# MKW21Z4 register map
Vendor: Freescale Semiconductor, Inc.; Series: Kinetis_W; File version: 1.6
CPU: CM0PLUS r0p0, little endian, no MPU, no FPU, VTOR, 2 interrupt priority bits
Registers are 16-bit, read-write, no defined reset value unless marked. A register's access mark holds for its fields unless they carry their own. Offsets are from the block's base; [hi:lo] are bit positions; {n}, {i} and the like mark numbered series.

## XCVR_CTRL_REGS — XCVR_MISC
Base 0x4005C280
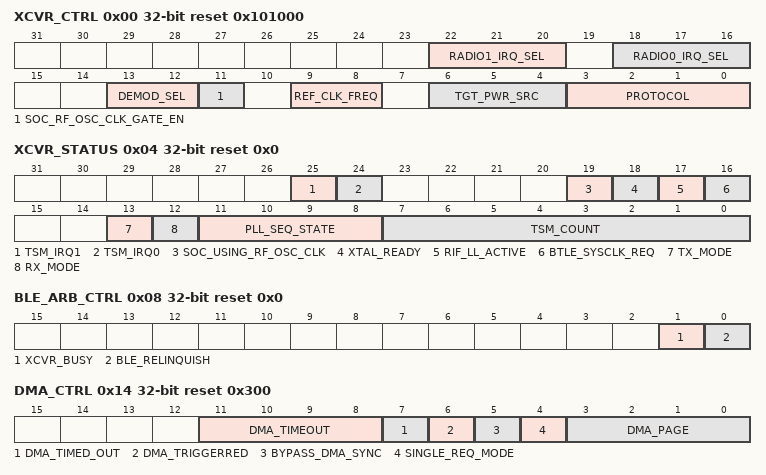
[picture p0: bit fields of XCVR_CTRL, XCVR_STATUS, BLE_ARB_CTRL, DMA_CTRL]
0x00 XCVR_CTRL 32-bit reset 0x101000 — TRANSCEIVER CONTROL
  [22:20] RADIO1_IRQ_SEL
    0=Assign Radio #1 Interrupt to BLE; 1=Assign Radio #1 Interrupt to 802.15.4; 2=Assign Radio #1 Interrupt to ANT; 3=Assign Radio #1 Interrupt to GENERIC_FSK; {v}=Radio #1 Interrupt unassigned (v=4..7)
  [18:16] RADIO0_IRQ_SEL
    0=Assign Radio #0 Interrupt to BLE; 1=Assign Radio #0 Interrupt to 802.15.4; 2=Assign Radio #0 Interrupt to ANT; 3=Assign Radio #0 Interrupt to GENERIC_FSK; {v}=Radio #0 Interrupt unassigned (v=4..7)
  [13:12] DEMOD_SEL — Demodulator Selector
    0=No demodulator selected; 1=Use Freescale Constant Envelope demodulator; 2=Use Legacy 802.15.4 demodulator
  [11] SOC_RF_OSC_CLK_GATE_EN
  [9:8] REF_CLK_FREQ — Radio Reference Clock Frequency
    0=32 MHz; 1=26 MHz
  [6:4] TGT_PWR_SRC — Target Power Source
  [3:0] PROTOCOL — Radio Protocol Selection
    0=BLE; 1=BLE in MBAN; 2=BLE overlap MBAN; 3=ANT; 4=Zigbee; 5=802.15.4j; 6=128 Channel FSK; 7=128 Channel GFSK; 8=Generic FSK; 9=MSK
0x04 XCVR_STATUS 32-bit reset 0x0 (reset mask 0xFFF0C000) — TRANSCEIVER STATUS
  [25] TSM_IRQ1 — TSM Interrupt #1
    0=TSM Interrupt #1 is not asserted; 1=TSM Interrupt #1 is asserted. Write '1' to this bit to clear it.
  [24] TSM_IRQ0 — TSM Interrupt #0
    0=TSM Interrupt #0 is not asserted; 1=TSM Interrupt #0 is asserted. Write '1' to this bit to clear it.
  [19] SOC_USING_RF_OSC_CLK ro — SOC Using RF Clock Indication
  [18] XTAL_READY ro — RF Osciallator Xtal Ready
    0=Indicates that the RF Oscillator is disabled or has not completed its warmup; 1=Indicates that the RF Oscillator has completed its warmup count and is ready for use
  [17] RIF_LL_ACTIVE ro — Link Layer Active Indication
  [16] BTLE_SYSCLK_REQ ro — BTLE System Clock Request
  [13] TX_MODE ro — Transmit Mode
  [12] RX_MODE ro — Receive Mode
  [11:8] PLL_SEQ_STATE ro — PLL Sequence State
    0=PLL OFF; 2=CTUNE; 3=CTUNE_SETTLE; 6=HPMCAL1; 8=HPMCAL1_SETTLE; 10=HPMCAL2; 12=HPMCAL2_SETTLE; 15=PLLREADY
  [7:0] TSM_COUNT ro
0x08 BLE_ARB_CTRL 32-bit reset 0x0 — BLE ARBITRATION CONTROL
  [1] XCVR_BUSY ro — Transceiver Busy Status Bit
    0=RF Channel in available (TSM is idle); 1=RF Channel in use (TSM is busy)
  [0] BLE_RELINQUISH — BLE Relinquish Control
0x10 OVERWRITE_VER 32-bit reset 0x0 — OVERWRITE VERSION
  [7:0] OVERWRITE_VER — Overwrite Version Number.
0x14 DMA_CTRL 32-bit reset 0x300 — TRANSCEIVER DMA CONTROL
  [11:8] DMA_TIMEOUT
  [7] DMA_TIMED_OUT — DMA Transfer Timed Out
    0=A DMA timeout has not occurred; 1=A DMA timeout has occurred in Single Request Mode since the last time this bit was cleared
  [6] DMA_TRIGGERRED ro
  [5] BYPASS_DMA_SYNC — Bypass External DMA Synchronization
    0=Don't Bypass External Synchronization. Use this setting if SINGLE_REQ_MODE=1.; 1=Bypass External Synchronization. This setting is mandatory if SINGLE_REQ_MODE=0.
  [4] SINGLE_REQ_MODE — DMA Single Request Mode
    0=Disable Single Request Mode. The transceiver will assert ipd_req_radio_rx whenever it has a new sample ready for transfer.; 1=Enable Single Request Mode. A single initial request by the transceiver will transfer the entire DMA block of data
  [3:0] DMA_PAGE — Transceiver DMA Page Selector
    0=DMA Idle; 1=RX_DIG I and Q; 2=RX_DIG I Only; 3=RX_DIG Q Only; 4=RAW ADC I and Q; 5=RAW ADC I Only; 6=RAW ADC Q only; 7=DC Estimator I and Q; 8=DC Estimator I Only; 9=DC Estimator Q only; 10=RX_DIG Phase Output; 11=Demodulator Hard Decision; 12=Demodulator Soft Decision; 13=Demodulator Data Output; 14=Demodulator CFO Phase Output
0x18 DMA_DATA 32-bit ro reset 0x0 — TRANSCEIVER DMA DATA
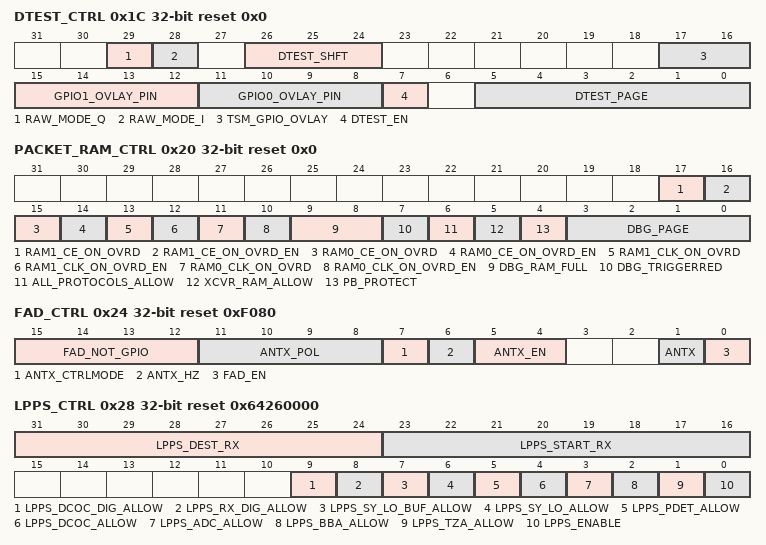
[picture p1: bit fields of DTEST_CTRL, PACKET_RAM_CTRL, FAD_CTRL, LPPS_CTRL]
0x1C DTEST_CTRL 32-bit reset 0x0 — DIGITAL TEST MUX CONTROL
  [29] RAW_MODE_Q — DTEST Raw Mode Enable for Q Channel
  [28] RAW_MODE_I — DTEST Raw Mode Enable for I Channel
  [26:24] DTEST_SHFT — DTEST Shift Control
  [17:16] TSM_GPIO_OVLAY — TSM GPIO Overlay Pin Control
    0=there is no overlay, and the DTEST Page Table dictates the node that appears on each DTEST pin; 1=the register GPIO0_OVLAY_PIN[3:0] selects the DTEST pin on which GPIO0_TRIG_EN will appear
  [15:12] GPIO1_OVLAY_PIN — GPIO 1 Overlay Pin
  [11:8] GPIO0_OVLAY_PIN — GPIO 0 Overlay Pin
  [7] DTEST_EN — DTEST Enable
    0=Disables DTEST. The DTEST pins assume their mission function.; 1=Enables DTEST. The contents of the selected page (DTEST_PAGE) will appear on the DTEST output pins.
  [5:0] DTEST_PAGE — DTEST Page Selector
0x20 PACKET_RAM_CTRL 32-bit reset 0x0 — PACKET RAM CONTROL
  [17] RAM1_CE_ON_OVRD — Override value for RAM1 CE (Chip Enable)
  [16] RAM1_CE_ON_OVRD_EN — Override control for RAM1 CE (Chip Enable)
    0=Normal operation; 1=Use the state of RAM1_CE_ON_OVRD to override the RAM1 CE
  [15] RAM0_CE_ON_OVRD — Override value for RAM0 CE (Chip Enable)
  [14] RAM0_CE_ON_OVRD_EN — Override control for RAM0 CE (Chip Enable)
    0=Normal operation; 1=Use the state of RAM0_CE_ON_OVRD to override the RAM0 CE
  [13] RAM1_CLK_ON_OVRD — Override value for RAM1 Clock Gate Enable
  [12] RAM1_CLK_ON_OVRD_EN — Override control for RAM1 Clock Gate Enable
    0=Normal operation; 1=Use the state of RAM1_CLK_ON_OVRD to override the RAM1 Clock Gate Enable
  [11] RAM0_CLK_ON_OVRD — Override value for RAM0 Clock Gate Enable
  [10] RAM0_CLK_ON_OVRD_EN — Override control for RAM0 Clock Gate Enable
    0=Normal operation; 1=Use the state of RAM0_CLK_ON_OVRD to override the RAM0 Clock Gate Enable
  [9:8] DBG_RAM_FULL ro — DBG_RAM_FULL[1:0]
    0=Neither Packet RAM0 nor RAM1 is full; 0bx1=Packet RAM0 has been filled to capacity; 0b1x=Packet RAM1 has been filled to capacity
  [7] DBG_TRIGGERRED ro
  [6] ALL_PROTOCOLS_ALLOW — Allow IPS bus access to Packet RAM for any protocol at any time.
    0=IPS bus access to Packet RAM is restricted to the protocol engine currently selected by XCVR_CTRL[PROTOCOL]; 1=All IPS bus access to Packet RAM permitted, regardless of XCVR_CTRL[PROTOCOL] setting
  [5] XCVR_RAM_ALLOW — Allow Packet RAM Transceiver Access
    0=Protocol Engines, and associated IPS busses, have exclusive access to Packet RAM (mission mode); 1=Transceiver-space access to Packet RAM, including Packet RAM debug mode, are allowed
  [4] PB_PROTECT — Packet Buffer Protect
    0=Incoming received packets overwrite Packet Buffer RX contents (default); 1=Incoming received packets are blocked from overwriting Packet Buffer RX contents
  [3:0] DBG_PAGE — Packet RAM Debug Page Selector
    0=Packet RAM Debug Mode Idle; 1=RX_DIG I and Q; 4=RAW ADC I and Q; 7=DC Estimator I and Q; 10=RX_DIG Phase Output; 11=Demodulator Hard Decision; 12=Demodulator Soft Decision; 13=Demodulator Data Output; 14=Demodulator CFO Phase Output
0x24 FAD_CTRL 32-bit reset 0xF080 — FAD CONTROL
  [15:12] FAD_NOT_GPIO — FAD versus GPIO Mode Selector
  [11:8] ANTX_POL — FAD Antenna Controls Polarity
  [7] ANTX_CTRLMODE — Antenna Diversity Control Mode
  [6] ANTX_HZ — FAD PAD Tristate Control
    0=ANT_A, ANT_B, RX_SWITCH and TX_SWITCH are actively driven outputs; 1=Antenna controls high impedance- Set ANT_A, ANT_B, RX_SWITCH and TX_SWITCH in high impedance
  [5:4] ANTX_EN — FAD Antenna Controls Enable
    0=all disabled (held low); 1=only RX/TX_SWITCH enabled; 2=only ANT_A/B enabled; 3=all enabled
  [1] ANTX — Antenna Selection State
  [0] FAD_EN — Fast Antenna Diversity Enable
    0=Fast Antenna Diversity disabled; 1=Fast Antenna Diversity enabled for 802.15.4
0x28 LPPS_CTRL 32-bit reset 0x64260000 — LOW POWER PREAMBLE SEARCH CONTROL
  [31:24] LPPS_DEST_RX — LPPS Fast TSM RX Warmup "Jump-to" Point
  [23:16] LPPS_START_RX — LPPS Fast TSM RX Warmup "Jump-from" Point
  [9] LPPS_DCOC_DIG_ALLOW
  [8] LPPS_RX_DIG_ALLOW
  [7] LPPS_SY_LO_BUF_ALLOW
  [6] LPPS_SY_LO_ALLOW
  [5] LPPS_PDET_ALLOW
  [4] LPPS_DCOC_ALLOW
  [3] LPPS_ADC_ALLOW
  [2] LPPS_BBA_ALLOW
  [1] LPPS_TZA_ALLOW
  [0] LPPS_ENABLE
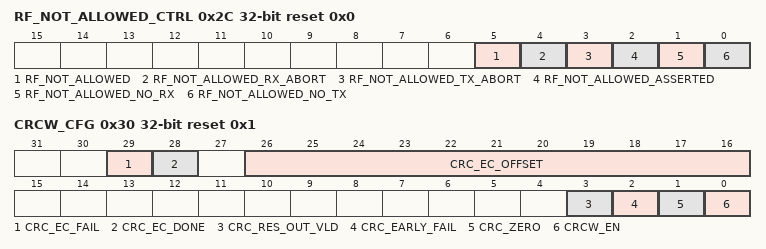
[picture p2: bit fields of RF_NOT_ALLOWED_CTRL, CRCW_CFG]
0x2C RF_NOT_ALLOWED_CTRL 32-bit reset 0x0 — WIFI COEXISTENCE CONTROL
  [5] RF_NOT_ALLOWED ro
  [4] RF_NOT_ALLOWED_RX_ABORT
    0=A RX abort due to assertion on RF_NOT_ALLOWED has not occurred; 1=A RX abort due to assertion on RF_NOT_ALLOWED has occurred since the last time this bit was cleared
  [3] RF_NOT_ALLOWED_TX_ABORT
    0=A TX abort due to assertion on RF_NOT_ALLOWED has not occurred; 1=A TX abort due to assertion on RF_NOT_ALLOWED has occurred since the last time this bit was cleared
  [2] RF_NOT_ALLOWED_ASSERTED
    0=Assertion on RF_NOT_ALLOWED has not occurred; 1=Assertion on RF_NOT_ALLOWED has occurred since the last time this bit was cleared
  [1] RF_NOT_ALLOWED_NO_RX
    0=Assertion on RF_NOT_ALLOWED has no effect on RX; 1=Assertion on RF_NOT_ALLOWED can abort RX
  [0] RF_NOT_ALLOWED_NO_TX
    0=Assertion on RF_NOT_ALLOWED has no effect on TX; 1=Assertion on RF_NOT_ALLOWED can abort TX
0x30 CRCW_CFG 32-bit reset 0x1 — CRC/WHITENER CONTROL
  [29] CRC_EC_FAIL ro — CRC error correction fail
  [28] CRC_EC_DONE ro — CRC error correction done
  [26:16] CRC_EC_OFFSET ro — CRC error correction offset
  [3] CRC_RES_OUT_VLD ro — CRC result output valid
  [2] CRC_EARLY_FAIL ro — CRC error correction fail
  [1] CRC_ZERO ro
  [0] CRCW_EN — CRC calculation enable
0x34 CRC_EC_MASK 32-bit ro reset 0x0 — CRC ERROR CORRECTION MASK
  [31:0] CRC_EC_MASK — CRC error correction mask
0x38 CRC_RES_OUT 32-bit ro reset 0x0 — CRC RESULT
  [31:0] CRC_RES_OUT — CRC result output
